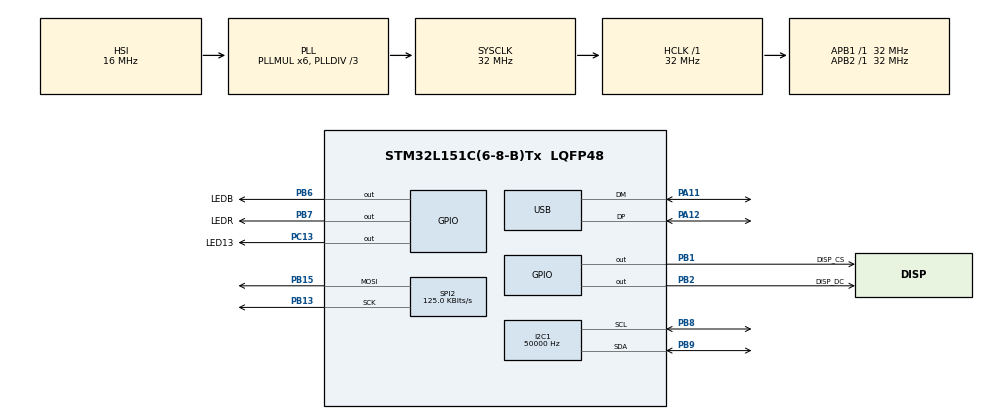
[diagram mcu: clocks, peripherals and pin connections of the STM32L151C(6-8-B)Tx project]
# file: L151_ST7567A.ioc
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I2C1.ClockSpeed=50000
Mcu.Family=STM32L1
Mcu.Name=STM32L151C(6-8-B)Tx
Mcu.Package=LQFP48
NVIC.PriorityGroup=NVIC_PRIORITYGROUP_4
NVIC.USB_LP_IRQn=true\:0\:0\:false\:false\:true\:false\:true\:true
PA11.Mode=Device
PA11.Signal=USB_DM
PA12.Mode=Device
PA12.Signal=USB_DP
PA13.Mode=Serial_Wire
PA13.Signal=SYS_JTMS-SWDIO
PA14.Mode=Serial_Wire
PA14.Signal=SYS_JTCK-SWCLK
PB1.GPIO_Label=DISP_CS
PB1.GPIO_Speed=GPIO_SPEED_FREQ_VERY_HIGH
PB1.PinState=GPIO_PIN_SET
PB1.Signal=GPIO_Output
PB13.Mode=TX_Only_Simplex_Unidirect_Master
PB13.Signal=SPI2_SCK
PB15.Mode=TX_Only_Simplex_Unidirect_Master
PB15.Signal=SPI2_MOSI
PB2.GPIO_Label=DISP_DC
PB2.GPIO_Speed=GPIO_SPEED_FREQ_VERY_HIGH
PB2.PinState=GPIO_PIN_SET
PB2.Signal=GPIO_Output
PB6.GPIO_Label=LEDB
PB6.GPIO_Speed=GPIO_SPEED_FREQ_VERY_HIGH
PB6.Signal=GPIO_Output
PB7.GPIO_Label=LEDR
PB7.GPIO_Speed=GPIO_SPEED_FREQ_VERY_HIGH
PB7.Signal=GPIO_Output
PB8.Mode=I2C
PB8.Signal=I2C1_SCL
PB9.Mode=I2C
PB9.Signal=I2C1_SDA
PC13-WKUP2.GPIO_Label=LED13
PC13-WKUP2.GPIO_Speed=GPIO_SPEED_FREQ_VERY_HIGH
PC13-WKUP2.Signal=GPIO_Output
ProjectManager.HeapSize=0x200
ProjectManager.StackSize=0x400
ProjectManager.TargetToolchain=STM32CubeIDE
RCC.48MHZClocksFreq_Value=48000000
RCC.AHBFreq_Value=32000000
RCC.APB1Freq_Value=32000000
RCC.APB1TimFreq_Value=32000000
RCC.APB2Freq_Value=32000000
RCC.APB2TimFreq_Value=32000000
RCC.HCLKFreq_Value=32000000
RCC.HSE_VALUE=12000000
RCC.HSI_VALUE=16000000
RCC.LSE_VALUE=32768
RCC.MSI_VALUE=2097000
RCC.PLLDIV=RCC_PLL_DIV3
RCC.PLLMUL=RCC_PLL_MUL6
RCC.PLLSource=RCC_PLLSOURCE_HSI
RCC.PLLSourceVirtualString=RCC_PLLSOURCE_HSI
RCC.SYSCLKFreq_VALUE=32000000
RCC.SYSCLKSource=RCC_SYSCLKSOURCE_PLLCLK
RCC.VCOOutputFreq_Value=96000000
SPI2.BaudRatePrescaler=SPI_BAUDRATEPRESCALER_256
SPI2.CLKPhase=SPI_PHASE_2EDGE
SPI2.CLKPolarity=SPI_POLARITY_HIGH
SPI2.CalculateBaudRate=125.0 KBits/s
SPI2.Direction=SPI_DIRECTION_2LINES
SPI2.Mode=SPI_MODE_MASTER
SPI2.VirtualType=VM_MASTER
USB_DEVICE.CLASS_NAME_FS=CDC
USB_DEVICE.VirtualMode=Cdc
USB_DEVICE.VirtualModeFS=Cdc_FS
VP_USB_DEVICE_VS_USB_DEVICE_CDC_FS.Mode=CDC_FS
board=custom

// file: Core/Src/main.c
/* USER CODE BEGIN Header */
/**
  ******************************************************************************
  * @file           : main.c
  * @brief          : Main program body
  ******************************************************************************
  * @attention
  *
  * Copyright (c) 2024 STMicroelectronics.
  * All rights reserved.
  *
  * This software is licensed under terms that can be found in the LICENSE file
  * in the root directory of this software component.
  * If no LICENSE file comes with this software, it is provided AS-IS.
  *
  ******************************************************************************
  */
/* USER CODE END Header */
#include "main.h"
#include "i2c.h"
#include "spi.h"
#include "usb_device.h"
#include "gpio.h"

void SystemClock_Config(void);

int main(void)
{

  /* MCU Configuration--------------------------------------------------------*/

  /* Reset of all peripherals, Initializes the Flash interface and the Systick. */
  HAL_Init();

  /* Configure the system clock */
  SystemClock_Config();

  /* Initialize all configured peripherals */
  MX_GPIO_Init();
  MX_USB_DEVICE_Init();
  MX_I2C1_Init();
  MX_SPI2_Init();

  /* Infinite loop */
  /* USER CODE BEGIN WHILE */
  while (1)
  {
	  kernel_main();
    /* USER CODE END WHILE */

  }
}

void SystemClock_Config(void)
{
  RCC_OscInitTypeDef RCC_OscInitStruct = {0};
  RCC_ClkInitTypeDef RCC_ClkInitStruct = {0};

  /** Configure the main internal regulator output voltage
  */
  __HAL_PWR_VOLTAGESCALING_CONFIG(PWR_REGULATOR_VOLTAGE_SCALE1);

  /** Initializes the RCC Oscillators according to the specified parameters
  * in the RCC_OscInitTypeDef structure.
  */
  RCC_OscInitStruct.OscillatorType = RCC_OSCILLATORTYPE_HSI;
  RCC_OscInitStruct.HSIState = RCC_HSI_ON;
  RCC_OscInitStruct.HSICalibrationValue = RCC_HSICALIBRATION_DEFAULT;
  RCC_OscInitStruct.PLL.PLLState = RCC_PLL_ON;
  RCC_OscInitStruct.PLL.PLLSource = RCC_PLLSOURCE_HSI;
  RCC_OscInitStruct.PLL.PLLMUL = RCC_PLL_MUL6;
  RCC_OscInitStruct.PLL.PLLDIV = RCC_PLL_DIV3;
  if (HAL_RCC_OscConfig(&RCC_OscInitStruct) != HAL_OK)
  {
    Error_Handler();
  }

  /** Initializes the CPU, AHB and APB buses clocks
  */
  RCC_ClkInitStruct.ClockType = RCC_CLOCKTYPE_HCLK|RCC_CLOCKTYPE_SYSCLK
                              |RCC_CLOCKTYPE_PCLK1|RCC_CLOCKTYPE_PCLK2;
  RCC_ClkInitStruct.SYSCLKSource = RCC_SYSCLKSOURCE_PLLCLK;
  RCC_ClkInitStruct.AHBCLKDivider = RCC_SYSCLK_DIV1;
  RCC_ClkInitStruct.APB1CLKDivider = RCC_HCLK_DIV1;
  RCC_ClkInitStruct.APB2CLKDivider = RCC_HCLK_DIV1;

  if (HAL_RCC_ClockConfig(&RCC_ClkInitStruct, FLASH_LATENCY_1) != HAL_OK)
  {
    Error_Handler();
  }
}

void Error_Handler(void)
{
  __disable_irq();
  while (1)
  {
  }
}
